# VCP1_L3_MAIN register map
Vendor: Texas Instruments
Peripheral module from a debugger description file (folder DRA75x_DRA74x).
Registers are 32-bit, access per field, reset 0x0 unless marked. A register's access mark holds for its fields unless they carry their own. Offsets are as the file gives them; lines under a group give offsets from that group; [hi:lo] are bit positions; {n}, {i} and the like mark numbered series; 'fields as' and 'values as' point back to an identical list; <NAME> marks a mode.

## VCP1_L3_MAIN
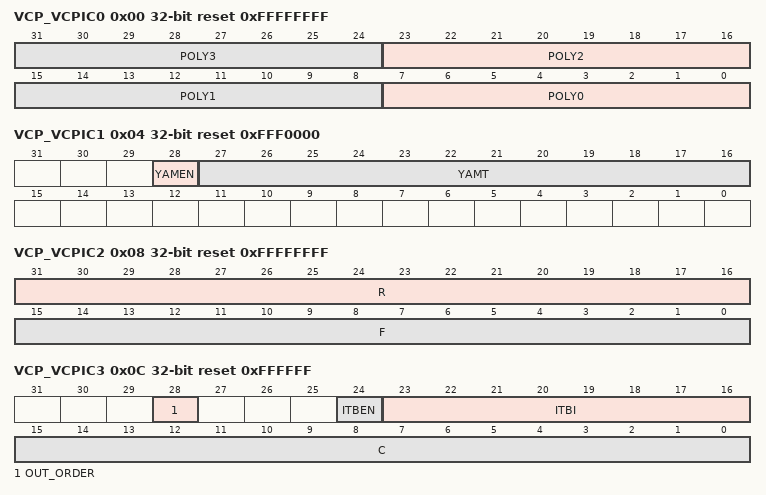
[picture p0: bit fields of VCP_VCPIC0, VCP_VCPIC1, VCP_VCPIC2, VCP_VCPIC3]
0x00 VCP_VCPIC0 rw reset 0xFFFFFFFF — The VCP version 2 Input Configuration Register 0
  [8n+7:8n] POLY{n} (n=0..3) — Polynomial generator G.
0x04 VCP_VCPIC1 reset 0xFFF0000 — The VCP version 2 Input Configuration Register 1
  [28] YAMEN rw — Yamamoto algorithm enable bit.
    0=Yamamoto_algorithm_is_disabled; 1=Yamamoto_algorithm_is_enabled
  [27:16] YAMT rw — Yamamoto threshold value bits.
0x08 VCP_VCPIC2 rw reset 0xFFFFFFFF — The VCP version 2 Input Configuration Register 2
  [31:16] R — Reliability length bits.
  [15:0] F — Frame length bits.
0x0C VCP_VCPIC3 reset 0xFFFFFF — The VCP version 2 Input Configuration Register 3
  [28] OUT_ORDER rw — Defines the order of VCP output for decoded data.
    0=0_to_31; 1=31_to_0
  [24] ITBEN rw — Traceback state index enable/disable.
    0=Disabled; 1=Initialization of traceback starting state is enabled
  [23:16] ITBI rw — Traceback state index. The index of the starting state for the traceback unit.
  [15:0] C rw — Convergence distance bits. The length of the convergent section of the siding window. This is only used if F &gt; F + (K-1) in mixed mode, or if F &gt; F + C in convergence mode.
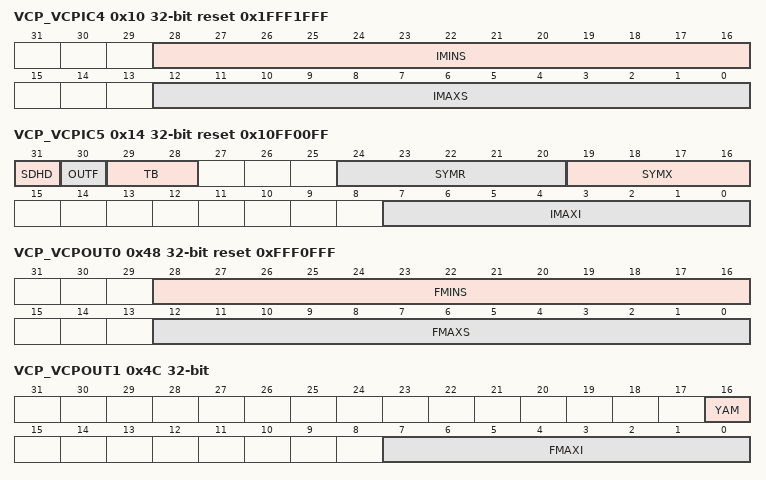
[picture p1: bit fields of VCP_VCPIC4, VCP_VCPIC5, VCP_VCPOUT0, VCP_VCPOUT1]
0x10 VCP_VCPIC4 reset 0x1FFF1FFF — The VCP version 2 Input Configuration Register 4
  [28:16] IMINS rw — Minimum initial state metric value bits. 13 bits.
  [12:0] IMAXS rw — Maximum initial state metric value bits. 13 bits.
0x14 VCP_VCPIC5 reset 0x10FF00FF — The VCP version 2 Input Configuration Register 5
  [31] SDHD rw — Output decision type select bit.
    0=Hard_decisions; 1=Soft_decisions
  [30] OUTF rw — Output parameters read flag bit.
    0=VCP_0 (VCPnREVT is not generated by VCP for output parameters read); 1=VCP_1 (VCPnREVT generated by VCP for output parameters read)
  [29:28] TB rw — Traceback mode select bits.
    1=Tailed,_F_≤_F_max._See; 2=Convergent,_(no_tail_bits); 3=F_F_3 (Mixed, F ≥ F max and tail bits are used. See)
  [24:20] SYMR rw — Determines decision buffer length in output FIFO. When programming register values for the SYMR bits, always subtract 1 from the value calculated. Valid values for the SYMR bits are from 0x0 to 0xF. For hard decision: If F ≤ 2048; then symr = ceil[F/64]-1; If F &gt; 2048; then symr = 15 or 31 For soft decision: If F ≤ 256; then symr = ceil[F/8]-1; If F &gt; 256; then symr = 15 or 31
  [19:16] SYMX rw — Determines branch metrics buffer length in input FIFO.
  [7:0] IMAXI rw — Maximum initial state metric value bits. IMAXI bits determine which state should be initialized with the maximum state metrics value (IMAXS) bits in VCPIC4; All the other states will be initialized with the value in the IMINS bits.
0x48 VCP_VCPOUT0 reset 0xFFF0FFF — The VCP version 2 Output Register 0
  [28:16] FMINS rw — Minimum initial state metric value for the final trellis stage. 13 bits.
  [12:0] FMAXS rw — Maximum state metric value for the final trellis stage (at trellis stage R+C). 13 bits.
0x4C VCP_VCPOUT1 (reset mask 0xFFFFFF00) — The VCP version 2 Output Register 1
  [16] YAM rw — Yamamoto bit result. This bit is a quality indicator bit and is only used if the Yamamoto logic is enabled.
    0=At least one trellis stage had an absolute difference less than the Yamamoto threshold and the decided frame has poor quality; 1=No trellis stage had an absolute difference less than the Yamamoto threshold and the frame has good quality
  [7:0] FMAXI rw — State index for the state with the final maximum state metric. There are 2(k-1) state metrics for each trellis stage. Valid range for FMAXI is 0 to 2(k-1) -1.
0x80 VCP_VCPWBM rw — VCP branch metrics write FIFO register
  [31:0] WBM — VCP branch metrics write FIFO
0xC0 VCP_VCPRDECS ro — VCP decisions read FIFO register
  [31:0] RDECS — VCP decisions read FIFO
